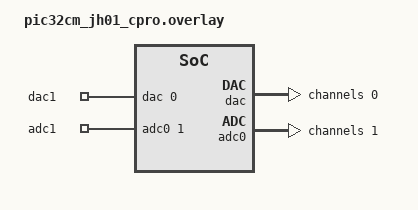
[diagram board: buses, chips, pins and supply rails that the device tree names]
/*
 * Copyright (c) 2026 Microchip Technology Inc.
 *
 * SPDX-License-Identifier: Apache-2.0
 */

/* Connect the PA02 (DAC-OUT) to PA04 (ADC AIN4) for the test */

/ {
	zephyr,user {
		io-channels = <&dac 0 &adc0 1>;
		io-channel-names = "dac1", "adc1";
	};
};

&dac {
	refsel = "a_vdd";
	#address-cells = <1>;
	#size-cells = <0>;
	status = "okay";

	channel@0 {
		reg = <0>;
		zephyr,resolution = <10>;
	};
};

&adc0 {
	#address-cells = <1>;
	#size-cells = <0>;
	status = "okay";

	channel@1 {
		reg = <1>;
		zephyr,gain = "ADC_GAIN_1";
		zephyr,reference = "ADC_REF_VDD_1";
		zephyr,acquisition-time = <ADC_ACQ_TIME_DEFAULT>;
		zephyr,resolution = <10>;
		zephyr,input-positive = <MCHP_ADC_AIN4>;
	};
};
